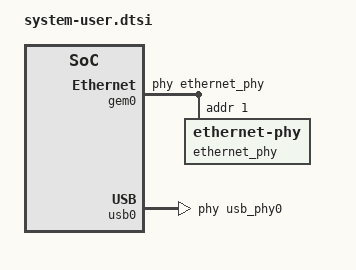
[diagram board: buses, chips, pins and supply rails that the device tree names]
/ {	
	chosen {
		bootargs = "earlycon console=ttyPS0,115200 clk_ignore_unused root=/dev/mmcblk0p2 rw rootwait uio_pdrv_genirq.of_id=generic-uio cpuidle.off=1";
	};

	
        usb_phy0: phy0 {
                compatible = "ulpi-phy";
                #phy-cells = <0>;
                reg = <0xe0002000 0x1000>;
                view-port = <0x170>;
                drv-vbus;
        };
};


&gem0 {
	local-mac-address = [00 0a 35 01 02 03];
	phy-handle = <&ethernet_phy>;
	ethernet_phy: ethernet-phy@1{
		reg = <1>;
	};
};

&usb0 {
        usb-phy = <&usb_phy0>;
};

&qspi {
        compatible = "jedec,spi-nor";
        reg = <0x0>;
        spi-tx-bus-width = <1>;
        spi-rx-bus-width = <4>;
        spi-max-frequency = <100000000>;
};


